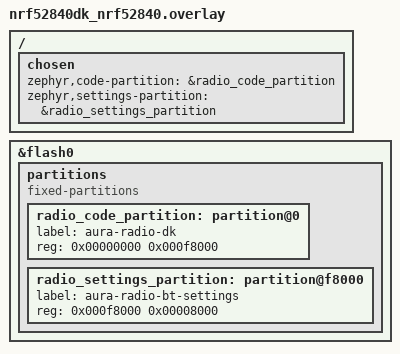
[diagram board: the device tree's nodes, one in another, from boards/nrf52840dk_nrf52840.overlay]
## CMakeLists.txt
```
cmake_minimum_required(VERSION 3.20.0)
# Reuse the reviewed passive PDM/NAND/control bindings without modifying bench.
list(APPEND DTS_ROOT ${CMAKE_CURRENT_SOURCE_DIR}
    ${CMAKE_CURRENT_SOURCE_DIR}/../bench ${CMAKE_CURRENT_SOURCE_DIR}/../drivers)
set(DTC_OVERLAY_FILE "${CMAKE_CURRENT_SOURCE_DIR}/boards/nrf52840dk_nrf52840.overlay")
find_package(Zephyr REQUIRED HINTS $ENV{ZEPHYR_BASE})
project(aura_a04_radio_dk)
if(NOT CONFIG_SOC_NRF52840 OR NOT CONFIG_BOARD_NRF52840DK OR NOT CONFIG_BT
   OR NOT CONFIG_BT_SMP_SC_ONLY OR NOT CONFIG_USE_DT_CODE_PARTITION
   OR NOT CONFIG_CSPRNG_ENABLED OR NOT CONFIG_HARDWARE_DEVICE_CS_GENERATOR
   OR NOT CONFIG_ENTROPY_NRF5_RNG OR CONFIG_TEST_RANDOM_GENERATOR OR CONFIG_TEST_CSPRNG_GENERATOR)
    message(FATAL_ERROR "Separate A04 radio application requires nrf52840dk/nrf52840, authenticated LE SC, isolated code partition and production nRF CSPRNG")
endif()
add_subdirectory(../drivers ${CMAKE_CURRENT_BINARY_DIR}/aura-drivers)
include(../cmake/opus-profile.cmake)
target_link_libraries(opus PUBLIC zephyr_interface)
target_compile_options(opus PRIVATE -ffunction-sections -fdata-sections -fstack-usage)
target_include_directories(app PRIVATE include ../include)
target_sources(app PRIVATE src/main.c src/aura_gatt_zephyr.c src/aura_pairing_zephyr.c
    ../src/aura_session_auth.c ../src/aura_transfer.c
    ../src/aura_opus.c ../src/aura_archive.c ../src/aura_journal.c
    ../src/aura_recorder.c ../src/aura_audio_zephyr.c
    ../src/aura_w25n01gv.c ../src/aura_w25n01gv_zephyr.c ../src/aura_control.c
    ../src/aura_release_auth.c ../src/aura_storage.c)
target_compile_options(app PRIVATE -fstack-usage -Wall -Wextra)
set_source_files_properties(src/main.c src/aura_gatt_zephyr.c src/aura_pairing_zephyr.c
    PROPERTIES COMPILE_OPTIONS "-Werror")
target_link_libraries(app PRIVATE opus)
```

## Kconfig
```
mainmenu "AURA A04 separate Bluetooth DK bench"
source "Kconfig.zephyr"
rsource "../drivers/Kconfig"
```

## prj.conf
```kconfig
# DK-only external PDM/NAND capture and authorized transfer integration.
CONFIG_STD_C11=y
CONFIG_PRINTK=y
CONFIG_CONSOLE=y
CONFIG_SERIAL=y
CONFIG_UART_CONSOLE=y
CONFIG_UART_INTERRUPT_DRIVEN=y
CONFIG_GPIO=y
CONFIG_SPI=y
CONFIG_HWINFO=y
CONFIG_AUDIO=y
CONFIG_AUDIO_DMIC=y
CONFIG_AUDIO_DMIC_NRFX_PDM=n
CONFIG_AURA_DMIC_NRFX_PDM=y

# sys_csrand_get must propagate hardware entropy errors, never timer/test bytes.
# CSPRNG_ENABLED is derived from ENTROPY_HAS_DRIVER (not a user-prompt option);
# CMake and the post-link report require its resolved value to be y.
CONFIG_ENTROPY_GENERATOR=y
CONFIG_ENTROPY_NRF5_RNG=y
CONFIG_ENTROPY_NRF5_BIAS_CORRECTION=y
CONFIG_ENTROPY_DEVICE_RANDOM_GENERATOR=y
CONFIG_HARDWARE_DEVICE_CS_GENERATOR=y
CONFIG_TEST_RANDOM_GENERATOR=n
CONFIG_TEST_CSPRNG_GENERATOR=n
CONFIG_TIMER_RANDOM_GENERATOR=n
CONFIG_XOSHIRO_RANDOM_GENERATOR=n
CONFIG_CTR_DRBG_CSPRNG_GENERATOR=n

# One peripheral link. L4 requires authenticated LE Secure Connections pairing;
# root main displays a fresh passkey only during its explicit local window.
CONFIG_BT=y
CONFIG_BT_PERIPHERAL=y
CONFIG_BT_DEVICE_NAME="AURA A04 DK"
CONFIG_BT_MAX_CONN=1
CONFIG_BT_MAX_PAIRED=1
CONFIG_BT_ID_MAX=1
CONFIG_BT_SMP=y
CONFIG_BT_SMP_APP_PAIRING_ACCEPT=y
CONFIG_BT_SMP_SC_ONLY=y
CONFIG_BT_SMP_SC_PAIR_ONLY=y
CONFIG_BT_SMP_ENFORCE_MITM=y
CONFIG_BT_FIXED_PASSKEY=n
CONFIG_BT_USE_DEBUG_KEYS=n
CONFIG_BT_STORE_DEBUG_KEYS=n
CONFIG_BT_KEYS_OVERWRITE_OLDEST=n
CONFIG_BT_BONDABLE=n
CONFIG_BT_FILTER_ACCEPT_LIST=y

# One immutable notification in flight; reserve additional protocol/SMP buffers.
# Generic adapter supports 23..517; this initial memory-bounded target caps247.
CONFIG_BT_L2CAP_TX_MTU=247
CONFIG_BT_BUF_ACL_TX_SIZE=251
CONFIG_BT_BUF_ACL_RX_SIZE=251
CONFIG_BT_BUF_ACL_TX_COUNT=3
CONFIG_BT_BUF_ACL_RX_COUNT_EXTRA=1
CONFIG_BT_L2CAP_TX_BUF_COUNT=3
CONFIG_BT_L2CAP_TX_FRAG_COUNT=2
CONFIG_BT_ATT_TX_COUNT=3
CONFIG_BT_ATT_PREPARE_COUNT=0
CONFIG_BT_GATT_ENFORCE_SUBSCRIPTION=y
CONFIG_BT_GATT_DYNAMIC_DB=n
CONFIG_BT_GATT_CACHING=n
CONFIG_BT_GATT_NOTIFY_MULTIPLE=n
CONFIG_BT_GATT_CLIENT=n
CONFIG_BT_EATT=n
CONFIG_BT_RECV_WORKQ_BT=y
CONFIG_BT_RX_STACK_SIZE=2048

# Internal NOR stores only BT identities/bonds/CCC; it is not owner-key storage.
# The owner context is explicitly supplied over trusted local UART after boot.
CONFIG_SETTINGS=y
CONFIG_BT_SETTINGS=y
CONFIG_BT_SETTINGS_CCC_STORE_MAX=4
CONFIG_BT_SETTINGS_CCC_LAZY_LOADING=y
CONFIG_BT_SETTINGS_CCC_STORE_ON_WRITE=y
CONFIG_FLASH=y
CONFIG_FLASH_MAP=y
CONFIG_FLASH_PAGE_LAYOUT=y
CONFIG_NVS=y
CONFIG_SETTINGS_NVS=y
CONFIG_SETTINGS_NVS_SECTOR_COUNT=8
CONFIG_SETTINGS_NVS_SECTOR_SIZE_MULT=1
CONFIG_SETTINGS_NVS_NAME_CACHE=n
CONFIG_NVS_LOOKUP_CACHE=n
CONFIG_NVS_INIT_BAD_MEMORY_REGION=n
CONFIG_USE_DT_CODE_PARTITION=y
CONFIG_BOOTLOADER_MCUBOOT=n

# Main owns explicit reader4096/storage49152 stacks; do not shrink codec stack.
CONFIG_MAIN_STACK_SIZE=2048
CONFIG_SYSTEM_WORKQUEUE_STACK_SIZE=4096
CONFIG_HEAP_MEM_POOL_SIZE=0
CONFIG_THREAD_STACK_INFO=y
CONFIG_INIT_STACKS=y
CONFIG_MPU_STACK_GUARD=y
CONFIG_ASSERT=y
CONFIG_SIZE_OPTIMIZATIONS=y
CONFIG_BUILD_OUTPUT_BIN=y
CONFIG_BUILD_OUTPUT_HEX=y
CONFIG_LOG=n
```

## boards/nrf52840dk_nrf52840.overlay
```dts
/* SPDX-License-Identifier: MIT */
/* Same external, electrically unqualified DK wiring as the separate bench.
 * This radio target does not change A04 wearable CAD or assign wearable pins. */
#include "../../bench/boards/nrf52840dk_nrf52840.overlay"

/* Standalone DK image: no MCUboot or OTA slot claim. Bound the linker to code
 * below the 32KiB internal NOR settings area; NAND control remains separate. */
&flash0 {
    /delete-node/ partitions;
    partitions {
        compatible = "fixed-partitions";
        #address-cells = <1>;
        #size-cells = <1>;
        radio_code_partition: partition@0 {
            label = "aura-radio-dk";
            reg = <0x00000000 0x000f8000>;
        };
        radio_settings_partition: partition@f8000 {
            label = "aura-radio-bt-settings";
            reg = <0x000f8000 0x00008000>;
        };
    };
};
/ {
    chosen {
        zephyr,code-partition = &radio_code_partition;
        zephyr,settings-partition = &radio_settings_partition;
    };
};
```

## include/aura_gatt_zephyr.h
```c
/* SPDX-License-Identifier: MIT */
#ifndef AURA_A04_GATT_ZEPHYR_H
#define AURA_A04_GATT_ZEPHYR_H
#include "aura_transfer.h"

#define AURA_GATT_AUTH_MAX 160u
#define AURA_GATT_FRAME_MAX 20u

/* Immutable copies, not bt_conn pointers or ownership credentials. A generation
 * changes on connection, security failure/loss, or CCC loss. Zero means no live
 * generation. A caller must not cache a trusted grant across that change. */
struct aura_gatt_link {
    uint64_t generation;
    uint16_t mtu;
    bool connected, secure_l4, subscribed, transfer_ready;
};
struct aura_gatt_auth_frame {
    uint64_t generation;
    uint8_t bytes, data[AURA_GATT_FRAME_MAX];
};
enum aura_gatt_authorization { AURA_GATT_DENIED=0, AURA_GATT_GRANTED=1 };
struct aura_gatt_owner_gate {
    uint64_t connection_generation;
    enum aura_gatt_authorization authorization;
    /* Local capture wins before transfer work. This cancels volatile transfer
     * work while retaining authenticated session/transaction high-water. */
    bool capture_preempt;
};

/* Call once before bt_enable/advertising. This registers the static service but
 * does not enable Bluetooth, advertise, pair, load keys or initialize transfer. */
void aura_gatt_init(void);
void aura_gatt_link_snapshot(struct aura_gatt_link *out);
struct bt_conn;
/* Pairing callbacks must bind their exact pointer, never another link snapshot. */
uint64_t aura_gatt_connection_generation(struct bt_conn *conn);

/* One serialized owner consumes auth writes and publishes immutable read data.
 * Auth characteristic 7f520003-1b15-4f0d-8fe5-3f942170a004 requires L4, accepts
 * only WRITE-with-response envelopes 4..20 and reads at most 160 bytes. These
 * APIs do not interpret credentials or grant access. No keys in diagnostics. */
bool aura_gatt_auth_take(struct aura_gatt_auth_frame *out);
int aura_gatt_auth_publish(uint64_t generation, const uint8_t *data, size_t bytes);
/* Absolute monotonic k_uptime_get() deadline from the TRUSTED proof provider.
 * Expiry closes the generation independently of storage-owner progress. Zero/
 * past times revoke; a positive deadline must be within INT32_MAX ms of now.
 * Only verified provider transitions may extend it; retries do not renew TTL. */
int aura_gatt_auth_deadline(uint64_t generation, int64_t absolute_ms);

/* ONLY this method calls aura_transfer APIs, all on the storage owner's thread.
 * Supply the separately verified session-provider result on EVERY tick. DENIED,
 * generation mismatch, or lost link ends the engine session before processing.
 * Drains completion, admits at most one mailbox command, steps at most once.
 * Returns 0 normally; an engine/admission error closes the link and returns that
 * exact negative result. It never manufactures a wire response. transfer must
 * be initialized by this same owner before a GRANTED tick. No NAND work occurs
 * in RX, connection, security, CCC, notification callbacks or radio workqueue. */
int aura_gatt_owner_tick(struct aura_transfer *transfer,
                         const struct aura_gatt_owner_gate *gate);

/* Owner requests, scheduled onto radio work. Disconnect invalidates admission
 * synchronously; security initiation alone never grants archive access. Pairing
 * window/passkey policy and authorization expiry belong to the application. */
void aura_gatt_disconnect(uint64_t generation);
void aura_gatt_request_security(uint64_t generation);
size_t aura_gatt_static_bytes(void);
#endif
```

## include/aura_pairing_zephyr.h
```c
/* SPDX-License-Identifier: MIT */
#ifndef AURA_A04_PAIRING_ZEPHYR_H
#define AURA_A04_PAIRING_ZEPHYR_H
#include <stdbool.h>
#include <stdint.h>

enum aura_pairing_event_kind {
    AURA_PAIRING_PASSKEY=0,
    AURA_PAIRING_CANCELLED,
    AURA_PAIRING_COMPLETE,
    AURA_PAIRING_EXPIRED
};
struct aura_pairing_event {
    enum aura_pairing_event_kind kind;
    uint32_t passkey;
    uint64_t window_generation, connection_generation;
};

/* Register dynamic passkey/auth-info callbacks once, before bt_enable. No
 * pairing window, radio, keys, ownership enrollment or automatic acceptance.
 * This module is the sole application writer of bt_set_bondable. */
int aura_pairing_init(void);
/* Caller must separately require trusted context and inactive capture. An
 * already-open window is idempotent and its absolute 60-second deadline does
 * not move. At most three accepted attempts; one exact connection at a time. */
int aura_pairing_open(void);
/* Invalidate display/window immediately and cancel/disconnect pending SMP.
 * Successfully completed bonds and owner keys are never deleted here. */
void aura_pairing_close(void);
bool aura_pairing_window_open(void);
/* Bounded owner-only drain. PASSKEY is returned only after current connection,
 * physical window and deadline revalidation. Print it only on trusted UART,
 * with exactly six digits. Other events never carry a passkey. */
bool aura_pairing_take(struct aura_pairing_event *event);
#endif
```

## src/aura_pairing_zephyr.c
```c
/* SPDX-License-Identifier: MIT */
#include "aura_pairing_zephyr.h"
#include "aura_gatt_zephyr.h"
#include <zephyr/kernel.h>
#include <zephyr/bluetooth/conn.h>
#include <errno.h>
#include <limits.h>
#include <string.h>

BUILD_ASSERT(IS_ENABLED(CONFIG_BT_SMP_SC_ONLY), "Pairing must require L4");
BUILD_ASSERT(IS_ENABLED(CONFIG_BT_SMP_APP_PAIRING_ACCEPT), "Physical gate is mandatory");
BUILD_ASSERT(!IS_ENABLED(CONFIG_BT_FIXED_PASSKEY), "No fixed passkey");
BUILD_ASSERT(!IS_ENABLED(CONFIG_BT_USE_DEBUG_KEYS), "No Bluetooth debug keys");
BUILD_ASSERT(!IS_ENABLED(CONFIG_BT_STORE_DEBUG_KEYS), "No stored debug keys");

#define WINDOW_MS INT64_C(60000)
#define ATTEMPTS_MAX 3u
#define EVENTS_MAX 2u
/* Public SMP Pairing Request/Response wire values from Core Vol3 PartH3.5.1;
 * Zephyr's names live in private host/smp.h, which is deliberately not used. */
#define SMP_AUTH_SC 0x08u
#define SMP_IO_KEYBOARD_ONLY 0x02u
#define SMP_IO_KEYBOARD_DISPLAY 0x04u

static struct {
    struct k_spinlock lock;
    struct k_work_delayable expiry;
    struct bt_conn *attempt;
    uint64_t counter, window, attempt_window, connection;
    int64_t deadline;
    unsigned attempts, event_count;
    struct aura_pairing_event events[EVENTS_MAX];
    bool initialized;
} pairing;
#define P pairing

static bool open_locked(int64_t now)
{ return P.initialized && P.window && now >= 0 && now < P.deadline; }
static void close_window_locked(void)
{
    P.window=0;P.deadline=0;
    /* Pinned Zephyr 4.2 bt_set_bondable is a nonblocking bool assignment.
     * This module is its sole application writer, ordered with window state. */
    bt_set_bondable(false);
}
static struct bt_conn *detach_locked(void)
{
    struct bt_conn *conn=P.attempt;
    P.attempt=NULL;P.attempt_window=P.connection=0;
    return conn;
}
static void terminal_locked(enum aura_pairing_event_kind kind,uint64_t connection)
{
    /* State changes discard queued passkeys, so a cancelled key cannot be
     * printed ahead of its cancellation even if the UART owner was blocked. */
    memset(P.events,0,sizeof(P.events));P.event_count=1;
    P.events[0]=(struct aura_pairing_event){.kind=kind,
        .window_generation=P.counter,.connection_generation=connection};
}
static void cancel_connection(struct bt_conn *conn,uint64_t generation)
{
    if(!conn)return;
    /* No policy spinlock is held: these calls may synchronously call back. */
    if(aura_gatt_connection_generation(conn)==generation){
        aura_gatt_disconnect(generation);
        (void)bt_conn_auth_cancel(conn);
    }
    bt_conn_unref(conn);
}
static void expire_if_due(void)
{
    struct bt_conn *conn=NULL;uint64_t generation=0;
    k_spinlock_key_t key=k_spin_lock(&P.lock);
    if(P.window && (k_uptime_get()<0 || k_uptime_get()>=P.deadline)){
        generation=P.connection;terminal_locked(AURA_PAIRING_EXPIRED,generation);
        close_window_locked();conn=detach_locked();
    }
    k_spin_unlock(&P.lock,key);
    cancel_connection(conn,generation);
}
static void expiry_work(struct k_work *work)
{
    ARG_UNUSED(work);expire_if_due();
    k_spinlock_key_t key=k_spin_lock(&P.lock);
    int64_t deadline=P.window?P.deadline:0;
    k_spin_unlock(&P.lock,key);
    if(deadline)(void)k_work_reschedule(&P.expiry,K_TIMEOUT_ABS_MS(deadline));
}
bool aura_pairing_window_open(void)
{
    k_spinlock_key_t key=k_spin_lock(&P.lock);
    bool allowed=open_locked(k_uptime_get());
    k_spin_unlock(&P.lock,key);return allowed;
}
int aura_pairing_open(void)
{
    expire_if_due();
    k_spinlock_key_t key=k_spin_lock(&P.lock);
    int64_t now=k_uptime_get();
    if(!P.initialized){k_spin_unlock(&P.lock,key);return -EACCES;}
    if(open_locked(now)){k_spin_unlock(&P.lock,key);return 0;}
    if(P.counter==UINT64_MAX || now<0 || now>INT64_MAX-WINDOW_MS){
        k_spin_unlock(&P.lock,key);return -EOVERFLOW;
    }
    P.window=++P.counter;P.deadline=now+WINDOW_MS;P.attempts=0;
    bt_set_bondable(true);
    memset(P.events,0,sizeof(P.events));P.event_count=0;
    int64_t deadline=P.deadline;
    k_spin_unlock(&P.lock,key);
    (void)k_work_reschedule(&P.expiry,K_TIMEOUT_ABS_MS(deadline));
    return 0;
}
void aura_pairing_close(void)
{
    k_spinlock_key_t key=k_spin_lock(&P.lock);
    uint64_t generation=P.connection;
    if(P.window||P.attempt)terminal_locked(AURA_PAIRING_CANCELLED,generation);
    close_window_locked();
    struct bt_conn *conn=detach_locked();
    k_spin_unlock(&P.lock,key);
    /* Do not cancel delayed work: an old close must not cancel a newly opened
     * window's timer. An obsolete work item rechecks the current deadline. */
    cancel_connection(conn,generation);
}

static enum bt_security_err accept(struct bt_conn *conn,const struct bt_conn_pairing_feat *feat)
{
    uint64_t generation=aura_gatt_connection_generation(conn);
    if(!generation||!feat)return BT_SECURITY_ERR_PAIR_NOT_ALLOWED;
    if(!(feat->auth_req&SMP_AUTH_SC)||feat->max_enc_key_size!=16||
       (feat->io_capability!=SMP_IO_KEYBOARD_ONLY&&feat->io_capability!=SMP_IO_KEYBOARD_DISPLAY))
        return BT_SECURITY_ERR_AUTH_REQUIREMENT;
    k_spinlock_key_t key=k_spin_lock(&P.lock);
    bool allowed=open_locked(k_uptime_get());
    if(allowed&&P.attempt){
        allowed=P.attempt==conn&&P.connection==generation&&P.attempt_window==P.window;
    }else if(allowed&&P.attempts<ATTEMPTS_MAX){
        memset(P.events,0,sizeof(P.events));P.event_count=0;
        P.attempt=bt_conn_ref(conn);P.connection=generation;P.attempt_window=P.window;
        ++P.attempts;
    }else allowed=false;
    k_spin_unlock(&P.lock,key);
    return allowed?BT_SECURITY_ERR_SUCCESS:BT_SECURITY_ERR_PAIR_NOT_ALLOWED;
}
static void failed_attempt(struct bt_conn *conn)
{
    struct bt_conn *release=NULL;uint64_t generation=0;
    k_spinlock_key_t key=k_spin_lock(&P.lock);
    if(P.attempt==conn){
        generation=P.connection;terminal_locked(AURA_PAIRING_CANCELLED,generation);
        release=detach_locked();
        if(P.attempts>=ATTEMPTS_MAX)close_window_locked();
    }
    k_spin_unlock(&P.lock,key);
    /* Even when the window remains open, a failed attempt requires a fresh
     * connection. Old callbacks cannot become a new attempt on this link. */
    cancel_connection(release,generation);
}
static void display(struct bt_conn *conn,unsigned int passkey)
{
    uint64_t generation=aura_gatt_connection_generation(conn);
    k_spinlock_key_t key=k_spin_lock(&P.lock);
    bool current=P.attempt==conn&&generation&&P.connection==generation&&
                 P.attempt_window==P.window&&open_locked(k_uptime_get());
    bool accepted=current&&passkey<=999999u;
    if(accepted){
        bool same=P.event_count&&P.events[P.event_count-1].kind==AURA_PAIRING_PASSKEY&&
                  P.events[P.event_count-1].passkey==passkey;
        if(!same){
            if(P.event_count==EVENTS_MAX)accepted=false;
            else P.events[P.event_count++]=(struct aura_pairing_event){
                .kind=AURA_PAIRING_PASSKEY,.passkey=passkey,
                .window_generation=P.window,.connection_generation=generation};
        }
    }
    bool owns=P.attempt==conn;
    k_spin_unlock(&P.lock,key);
    if(!accepted&&owns)failed_attempt(conn);
    /* A callback for a different old connection is ignored, never relabelled. */
}
static void cancelled(struct bt_conn *conn) { failed_attempt(conn); }
static void confirm(struct bt_conn *conn)
{
    /* Never approve a Just Works fallback, even inside the physical window. */
    failed_attempt(conn);
}
static void complete(struct bt_conn *conn,bool bonded)
{
    /* Bonding is persistence, not owner authorization. Even an authenticated
     * nonbonded link still requires ASC1; it cannot reconnect without pairing. */
    ARG_UNUSED(bonded);
    uint64_t generation=aura_gatt_connection_generation(conn);
    bool secure=bt_conn_get_security(conn)==BT_SECURITY_L4&&bt_conn_enc_key_size(conn)==16;
    struct bt_conn *release=NULL;bool success=false;
    k_spinlock_key_t key=k_spin_lock(&P.lock);
    if(P.attempt==conn){
        success=generation&&P.connection==generation&&P.attempt_window==P.window&&
                open_locked(k_uptime_get())&&secure;
        terminal_locked(success?AURA_PAIRING_COMPLETE:AURA_PAIRING_CANCELLED,P.connection);
        generation=P.connection;close_window_locked();release=detach_locked();
    }
    k_spin_unlock(&P.lock,key);
    if(success)bt_conn_unref(release);
    else cancel_connection(release,generation);
}
static void failed(struct bt_conn *conn,enum bt_security_err reason)
{ ARG_UNUSED(reason);failed_attempt(conn); }
static void disconnected(struct bt_conn *conn,uint8_t reason)
{
    ARG_UNUSED(reason);
    struct bt_conn *release=NULL;
    k_spinlock_key_t key=k_spin_lock(&P.lock);
    if(P.attempt==conn){
        terminal_locked(AURA_PAIRING_CANCELLED,P.connection);release=detach_locked();
        if(P.attempts>=ATTEMPTS_MAX)close_window_locked();
    }
    k_spin_unlock(&P.lock,key);
    if(release)bt_conn_unref(release);
}
BT_CONN_CB_DEFINE(aura_pairing_connection_callbacks)={.disconnected=disconnected};
static const struct bt_conn_auth_cb callbacks={.pairing_accept=accept,
    .passkey_display=display,.cancel=cancelled,.pairing_confirm=confirm};
static struct bt_conn_auth_info_cb info_callbacks={.pairing_complete=complete,.pairing_failed=failed};
int aura_pairing_init(void)
{
    if(P.initialized)return 0;
    k_work_init_delayable(&P.expiry,expiry_work);
    int result=bt_conn_auth_cb_register(&callbacks);
    if(result)return result;
    result=bt_conn_auth_info_cb_register(&info_callbacks);
    if(result){(void)bt_conn_auth_cb_register(NULL);return result;}
    P.initialized=true;bt_set_bondable(false);return 0;
}
bool aura_pairing_take(struct aura_pairing_event *event)
{
    if(!event)return false;
    memset(event,0,sizeof(*event));expire_if_due();
    for(unsigned scanned=0;scanned<EVENTS_MAX;++scanned){
        struct bt_conn *conn=NULL;struct aura_pairing_event candidate;
        k_spinlock_key_t key=k_spin_lock(&P.lock);
        if(!P.event_count){k_spin_unlock(&P.lock,key);return false;}
        candidate=P.events[0];--P.event_count;
        if(P.event_count)P.events[0]=P.events[1];
        memset(&P.events[P.event_count],0,sizeof(P.events[0]));
        bool valid=candidate.window_generation==P.counter;
        if(candidate.kind==AURA_PAIRING_PASSKEY){
            valid=valid&&open_locked(k_uptime_get())&&P.window==candidate.window_generation&&
                  P.attempt&&P.connection==candidate.connection_generation;
            if(valid)conn=bt_conn_ref(P.attempt);
        }
        k_spin_unlock(&P.lock,key);
        if(conn){
            uint64_t generation=aura_gatt_connection_generation(conn);
            key=k_spin_lock(&P.lock);
            valid=valid&&generation==candidate.connection_generation&&P.attempt==conn&&
                  P.window==candidate.window_generation&&open_locked(k_uptime_get());
            k_spin_unlock(&P.lock,key);bt_conn_unref(conn);
        }
        if(valid){*event=candidate;return true;}
    }
    return false;
}
```
